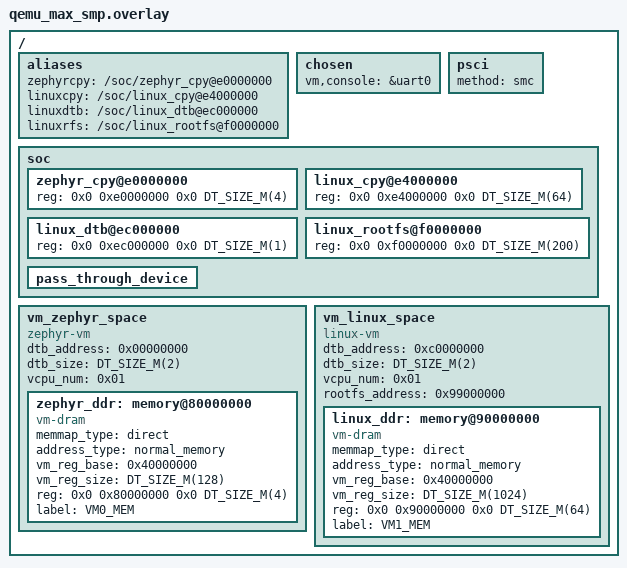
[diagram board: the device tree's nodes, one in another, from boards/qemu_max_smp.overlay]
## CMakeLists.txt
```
# Copyright 2024-2025 HNU-ESNL: Guoqi Xie, Chenglai Xiong, Xingyu Hu and etc.
# Copyright 2024-2025 openEuler SIG-Zephyr
# SPDX-License-Identifier: Apache-2.0

#Add env for build zvm
set(CMAKE_PREFIX_PATH ${CMAKE_CURRENT_SOURCE_DIR}/../..)

cmake_minimum_required(VERSION 3.20.0)
find_package(Zephyr REQUIRED HINTS $ENV{ZEPHYR_BASE})
project(zvm)

target_sources(app PRIVATE src/main.c)
```

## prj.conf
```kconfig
# Copyright 2024-2025 HNU-ESNL: Guoqi Xie, Chenglai Xiong, Xingyu Hu and etc.
# Copyright 2024-2025 openEuler SIG-Zephyr
# SPDX-License-Identifier: Apache-2.0

# ZVM
CONFIG_ZVM=y
CONFIG_ZVM_DEBUG_LOG_INFO=y
CONFIG_MAX_VM_NUM=2
CONFIG_MAX_VCPU_PER_VM=2
CONFIG_VM_DTB_FILE_INPUT=y
CONFIG_KERNEL_BIN_NAME="zvm_host"

CONFIG_CONSOLE=y
CONFIG_CONSOLE_SUBSYS=y
CONFIG_CONSOLE_GETLINE=y
CONFIG_UART_CONSOLE=y
CONFIG_SHELL=y
CONFIG_SHELL_GETOPT=y
CONFIG_SHELL_THREAD_PRIORITY_OVERRIDE=y
CONFIG_SHELL_THREAD_PRIORITY=4
CONFIG_SHELL_PROMPT_UART="zvm_host:~#"
CONFIG_LOG=y
CONFIG_LOG_MODE_MINIMAL=y
CONFIG_ASSERT=y

CONFIG_MINIMAL_LIBC=y
CONFIG_MINIMAL_LIBC_RAND=y
CONFIG_COMMON_LIBC_MALLOC_ARENA_SIZE=4096
CONFIG_GETOPT_LONG=y
CONFIG_POSIX_C_LIB_EXT=y

CONFIG_PRINTK_BUFFER_SIZE=128
CONFIG_SHELL_CMD_BUFF_SIZE=4096
CONFIG_SHELL_PRINTF_BUFF_SIZE=128
CONFIG_ISR_STACK_SIZE=8192
CONFIG_SHELL_STACK_SIZE=8192
CONFIG_SYSTEM_WORKQUEUE_STACK_SIZE=8192
CONFIG_PRIVILEGED_STACK_SIZE=8192
# 64MB heap size.
CONFIG_HEAP_MEM_POOL_SIZE=67108864

CONFIG_THREAD_NAME=y
CONFIG_THREAD_STACK_INFO=y
CONFIG_SCHED_CPU_MASK=y
CONFIG_SCHED_CPU_MASK_PIN_ONLY=y
CONFIG_NUM_PREEMPT_PRIORITIES=15
CONFIG_TIMING_FUNCTIONS=y
CONFIG_SCHED_DEADLINE=y
CONFIG_NO_OPTIMIZATIONS=y
CONFIG_DYNAMIC_INTERRUPTS=y

CONFIG_MAX_XLAT_TABLES=8192
CONFIG_MAX_DOMAIN_PARTITIONS=16
```

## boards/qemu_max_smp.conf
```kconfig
# Copyright 2024-2025 HNU-ESNL: Guoqi Xie, Chenglai Xiong, Xingyu Hu and etc.
# Copyright 2024-2025 openEuler SIG-Zephyr
# SPDX-License-Identifier: Apache-2.0

# hypervisor need 1024M of virtual space.
CONFIG_KERNEL_VM_SIZE=0x80000000

# virtual device.
CONFIG_ENABLE_VM_VGICV3=y
CONFIG_ENABLE_VM_VSERIAL=y

CONFIG_ARM64_SET_VMPIDR_EL2=y
CONFIG_ARM64_SET_VPIDR_EL2=y

# PSCI is supported
CONFIG_PM_CPU_OPS_PSCI=y
CONFIG_MP_MAX_NUM_CPUS=4

# Enable serial port
CONFIG_UART_PL011=y
```

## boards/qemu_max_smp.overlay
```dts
/*
 * Copyright 2024-2025 HNU-ESNL: Guoqi Xie, Chenglai Xiong, Xingyu Hu and etc.
 * Copyright 2024-2025 openEuler SIG-Zephyr
 *
 * SPDX-License-Identifier: Apache-2.0
 */

/{
	aliases {
		zephyrcpy = "/soc/zephyr_cpy@e0000000";
		linuxcpy = "/soc/linux_cpy@e4000000";
		linuxdtb = "/soc/linux_dtb@ec000000";
		linuxrfs = "/soc/linux_rootfs@f0000000";
	};

	chosen {
		vm,console = &uart0;
	};

	psci {
		method = "smc";
	};

	soc {
		zephyr_cpy@e0000000 {
			reg = <0x0 0xe0000000 0x0 DT_SIZE_M(4)>;
		};

		linux_cpy@e4000000 {
			reg = <0x0 0xe4000000 0x0 DT_SIZE_M(64)>;
		};

		linux_dtb@ec000000 {
			reg = <0x0 0xec000000 0x0 DT_SIZE_M(1)>;
		};

		linux_rootfs@f0000000 {
			reg = <0x0 0xf0000000 0x0 DT_SIZE_M(200)>;
		};

		pass_through_device {

			#address-cells = <2>;
			#size-cells = <2>;
			ranges;
			/* using pt device for vm */
		};

	};

	vm_zephyr_space {
		#address-cells = <2>;
		#size-cells = <2>;
		compatible = "zephyr-vm";
		dtb_address = <0x00000000>;
		dtb_size = <DT_SIZE_M(2)>;
		vcpu_num = <0x01>;

		zephyr_ddr: memory@80000000 {
			compatible = "vm-dram";
			memmap_type = "direct";
			address_type = "normal_memory";
			vm_reg_base = <0x40000000>;
			vm_reg_size = <DT_SIZE_M(128)>;
			reg = <0x0 0x80000000 0x0 DT_SIZE_M(4)>;
			label = "VM0_MEM";
		};
	};

	vm_linux_space {
		#address-cells = <2>;
		#size-cells = <2>;
		compatible = "linux-vm";
		dtb_address = <0xc0000000>;
		dtb_size = <DT_SIZE_M(2)>;
		vcpu_num = <0x01>;
		rootfs_address = <0x99000000>;

		linux_ddr: memory@90000000 {
			compatible = "vm-dram";
			memmap_type = "direct";
			address_type = "normal_memory";
			vm_reg_base = <0x40000000>;
			vm_reg_size = <DT_SIZE_M(1024)>;
			reg = <0x0 0x90000000 0x0 DT_SIZE_M(64)>;
			label = "VM1_MEM";
		};
	};
};
```

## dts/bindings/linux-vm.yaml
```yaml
description: linux virtual machine space

compatible: "linux-vm"

properties:
  dtb_address:
    type: int
    description: |
      Base address of the VM device tree file.
    required: true

  dtb_size:
    type: int
    description: |
      Size of the VM device tree file.
    required: true

  vcpu_num:
    type: int
    description: |
      Number of virtual CPUs for each Linux VM (supports SMP).
    required: true

  rootfs_address:
    type: int
    description: |
      Base address of the VM root filesystem.
    required: true
```

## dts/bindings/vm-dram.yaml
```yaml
description: Virtual Machine DRAM

compatible: "vm-dram"

properties:
  reg:
    type: array
    required: true
    description: |
      Memory regions for the VM.

  label:
    type: string
    required: true
    description: |
      Human-readable name for the VM DRAM.

  memmap_type:
    type: string
    required: true
    description: |
      Type of memory mapping for the VM domain.

  vm_reg_base:
    type: int
    required: true
    description: |
      Guest VM's physical memory base, equivalent to the common `memory reg base` in the DTS.

  vm_reg_size:
    type: int
    required: true
    description: |
      Guest VM's physical memory size, equivalent to the common `memory reg size` in the DTS.

  address_type:
    type: string
    required: true
    description: |
      Type of virtual address for the VM.
```

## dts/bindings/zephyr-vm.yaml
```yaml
description: Zephyr Virtual Machine Space

compatible: "zephyr-vm"

properties:
  dtb_address:
    type: int
    description: |
      Base address of the VM device tree file.
    required: true

  dtb_size:
    type: int
    description: |
      Size of the VM device tree file.
    required: true

  vcpu_num:
    type: int
    description: |
      Number of virtual CPUs for each Zephyr VM (supports SMP).
    required: true
```

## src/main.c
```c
/*
 * Copyright 2024-2025 HNU-ESNL: Guoqi Xie, Chenglai Xiong, Xingyu Hu and etc.
 * Copyright 2024-2025 openEuler SIG-Zephyr
 *
 * SPDX-License-Identifier: Apache-2.0
 */

#include <zephyr/kernel.h>
#include <zephyr/sys/printk.h>

static void zvm_print_log(void)
{
	printk("\n");
	printk("\n");
	printk("█████████╗    ██╗     ██╗    ███╗    ███╗\n");
	printk("╚════███╔╝    ██║     ██║    ████╗  ████║\n");
	printk("   ███╔╝      ╚██╗   ██╔╝    ██╔ ████╔██║\n");
	printk("  ██╔╝         ╚██  ██╔╝     ██║ ╚██╔╝██║\n");
	printk("█████████╗      ╚████╔╝      ██║  ╚═╝ ██║\n");
}

int main(int argc, char **argv)
{
	zvm_print_log();
	return 0;
}
```
